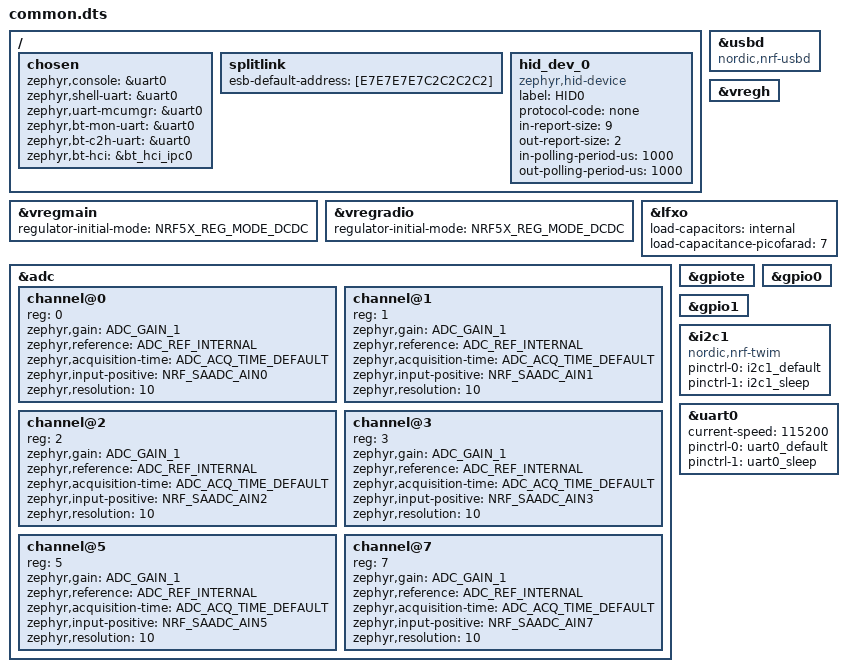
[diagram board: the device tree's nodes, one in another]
#include "pinctrl.dtsi"

#include "backlight.dts"
#include "battsense.dts"
#include "kb-handler.dts"

/ {

	chosen {
		zephyr,console = &uart0;
		zephyr,shell-uart = &uart0;
		zephyr,uart-mcumgr = &uart0;
		zephyr,bt-mon-uart = &uart0;
		zephyr,bt-c2h-uart = &uart0;

		zephyr,bt-hci = &bt_hci_ipc0;
	};

    splitlink: splitlink {
        esb-default-address = [E7E7E7E7C2C2C2C2];
    };

    hid_dev_0: hid_dev_0 {
		compatible = "zephyr,hid-device";
		label = "HID0";
		protocol-code = "none";
		in-report-size = <9>;
        out-report-size = <2>;
		in-polling-period-us = <1000>;
		out-polling-period-us = <1000>;
	};

};

zephyr_udc0: &usbd {
	compatible = "nordic,nrf-usbd";
	status = "okay";
};


&vregmain {
	regulator-initial-mode = <NRF5X_REG_MODE_DCDC>;
};

&vregradio {
	regulator-initial-mode = <NRF5X_REG_MODE_DCDC>;
};

&vregh {
	status = "okay";
};

&lfxo {
	load-capacitors = "internal";
	load-capacitance-picofarad = <7>;
};

&adc {
	status = "okay";

    #address-cells = <1>;
    #size-cells = <0>;

    channel@0 {
        reg = <0>;
        zephyr,gain = "ADC_GAIN_1";
        zephyr,reference = "ADC_REF_INTERNAL";
        zephyr,acquisition-time = <ADC_ACQ_TIME_DEFAULT>;
        zephyr,input-positive = <NRF_SAADC_AIN0>;
        zephyr,resolution = <10>;
    };
    channel@1 {
        reg = <1>;
        zephyr,gain = "ADC_GAIN_1";
        zephyr,reference = "ADC_REF_INTERNAL";
        zephyr,acquisition-time = <ADC_ACQ_TIME_DEFAULT>;
        zephyr,input-positive = <NRF_SAADC_AIN1>;
        zephyr,resolution = <10>;
    };
    channel@2 {
        reg = <2>;
        zephyr,gain = "ADC_GAIN_1";
        zephyr,reference = "ADC_REF_INTERNAL";
        zephyr,acquisition-time = <ADC_ACQ_TIME_DEFAULT>;
        zephyr,input-positive = <NRF_SAADC_AIN2>;
        zephyr,resolution = <10>;
    };
    channel@3 {
        reg = <3>;
        zephyr,gain = "ADC_GAIN_1";
        zephyr,reference = "ADC_REF_INTERNAL";
        zephyr,acquisition-time = <ADC_ACQ_TIME_DEFAULT>;
        zephyr,input-positive = <NRF_SAADC_AIN3>;
        zephyr,resolution = <10>;
    };
    channel@5 {
        reg = <5>;
        zephyr,gain = "ADC_GAIN_1";
        zephyr,reference = "ADC_REF_INTERNAL";
        zephyr,acquisition-time = <ADC_ACQ_TIME_DEFAULT>;
        zephyr,input-positive = <NRF_SAADC_AIN5>;
        zephyr,resolution = <10>;
    };
    channel@7 {
        reg = <7>;
        zephyr,gain = "ADC_GAIN_1";
        zephyr,reference = "ADC_REF_INTERNAL";
        zephyr,acquisition-time = <ADC_ACQ_TIME_DEFAULT>;
        zephyr,input-positive = <NRF_SAADC_AIN7>;
        zephyr,resolution = <10>;
    };

};

&gpiote {
	status = "okay";
};

&gpio0 {
	status = "okay";
};

&gpio1 {
	status = "okay";
};

&i2c1 {
	compatible = "nordic,nrf-twim";
	status = "okay";
	pinctrl-0 = <&i2c1_default>;
	pinctrl-1 = <&i2c1_sleep>;
	pinctrl-names = "default", "sleep";
};

&uart0 {
	status = "okay";
	current-speed = <115200>;
	pinctrl-0 = <&uart0_default>;
	pinctrl-1 = <&uart0_sleep>;
	pinctrl-names = "default", "sleep";
};
